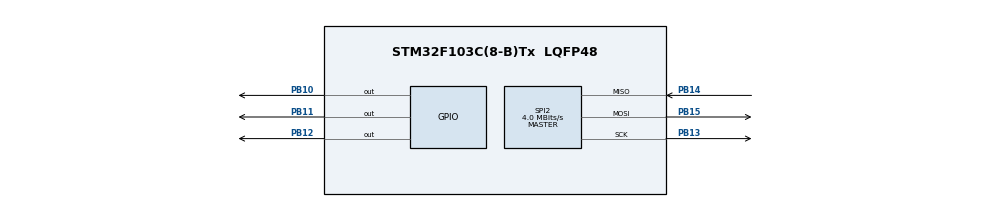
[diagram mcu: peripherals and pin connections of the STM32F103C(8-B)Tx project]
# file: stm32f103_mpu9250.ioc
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Mcu.Family=STM32F1
Mcu.Name=STM32F103C(8-B)Tx
Mcu.Package=LQFP48
NVIC.PriorityGroup=NVIC_PRIORITYGROUP_4
PA13.Mode=Serial_Wire
PA13.Signal=SYS_JTMS-SWDIO
PA14.Mode=Serial_Wire
PA14.Signal=SYS_JTCK-SWCLK
PB10.Signal=GPIO_Output
PB11.Signal=GPIO_Output
PB12.Signal=GPIO_Output
PB13.Mode=Full_Duplex_Master
PB13.Signal=SPI2_SCK
PB14.Mode=Full_Duplex_Master
PB14.Signal=SPI2_MISO
PB15.Mode=Full_Duplex_Master
PB15.Signal=SPI2_MOSI
PC14-OSC32_IN.Mode=LSE-External-Oscillator
PC14-OSC32_IN.Signal=RCC_OSC32_IN
PC15-OSC32_OUT.Mode=LSE-External-Oscillator
PC15-OSC32_OUT.Signal=RCC_OSC32_OUT
PD0-OSC_IN.Mode=HSE-External-Oscillator
PD0-OSC_IN.Signal=RCC_OSC_IN
PD1-OSC_OUT.Mode=HSE-External-Oscillator
PD1-OSC_OUT.Signal=RCC_OSC_OUT
ProjectManager.HeapSize=0x200
ProjectManager.StackSize=0x400
ProjectManager.TargetToolchain=STM32CubeIDE
RCC.APB1Freq_Value=8000000
RCC.APB2Freq_Value=8000000
SPI2.CalculateBaudRate=4.0 MBits/s
SPI2.Direction=SPI_DIRECTION_2LINES
SPI2.Mode=SPI_MODE_MASTER
SPI2.VirtualType=VM_MASTER
board=custom

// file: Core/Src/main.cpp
/* USER CODE BEGIN Header */
/**
  ******************************************************************************
  * @file           : main.c
  * @brief          : Main program body
  ******************************************************************************
  * @attention
  *
  * <h2><center>&copy; Copyright (c) 2020 STMicroelectronics.
  * All rights reserved.</center></h2>
  *
  * This software component is licensed by ST under BSD 3-Clause license,
  * the "License"; You may not use this file except in compliance with the
  * License. You may obtain a copy of the License at:
  *                        opensource.org/licenses/BSD-3-Clause
  *
  ******************************************************************************
  */
/* USER CODE END Header */

#include "../../Platform/PlatformInclude.h"

SPI_HandleTypeDef hspi2;

void SystemClock_Config(void);
static void MX_GPIO_Init(void);
static void MX_SPI2_Init(void);

int main(void)
{

  /* MCU Configuration--------------------------------------------------------*/

  /* Reset of all peripherals, Initializes the Flash interface and the Systick. */
  HAL_Init();

  /* Configure the system clock */
  SystemClock_Config();

  /* Initialize all configured peripherals */
  MX_GPIO_Init();
  MX_SPI2_Init();
  /* USER CODE BEGIN 2 */
  Mpu9250* Imu = Mpu9250::getInstance();
  Imu->configImu(MPU_SCALE_8G, MPU_SCALE_1000DPS);
  ImuData data = {0};
  /* USER CODE END 2 */

  /* Infinite loop */
  while (1)
  {
	Imu->getData(data);
	HAL_Delay(100);
  }
}

void SystemClock_Config(void)
{
  RCC_OscInitTypeDef RCC_OscInitStruct = {0};
  RCC_ClkInitTypeDef RCC_ClkInitStruct = {0};

  /** Initializes the CPU, AHB and APB busses clocks
  */
  RCC_OscInitStruct.OscillatorType = RCC_OSCILLATORTYPE_HSI;
  RCC_OscInitStruct.HSIState = RCC_HSI_ON;
  RCC_OscInitStruct.HSICalibrationValue = RCC_HSICALIBRATION_DEFAULT;
  RCC_OscInitStruct.PLL.PLLState = RCC_PLL_NONE;
  if (HAL_RCC_OscConfig(&RCC_OscInitStruct) != HAL_OK)
  {
    Error_Handler();
  }
  /** Initializes the CPU, AHB and APB busses clocks
  */
  RCC_ClkInitStruct.ClockType = RCC_CLOCKTYPE_HCLK|RCC_CLOCKTYPE_SYSCLK
                              |RCC_CLOCKTYPE_PCLK1|RCC_CLOCKTYPE_PCLK2;
  RCC_ClkInitStruct.SYSCLKSource = RCC_SYSCLKSOURCE_HSI;
  RCC_ClkInitStruct.AHBCLKDivider = RCC_SYSCLK_DIV1;
  RCC_ClkInitStruct.APB1CLKDivider = RCC_HCLK_DIV1;
  RCC_ClkInitStruct.APB2CLKDivider = RCC_HCLK_DIV1;

  if (HAL_RCC_ClockConfig(&RCC_ClkInitStruct, FLASH_LATENCY_0) != HAL_OK)
  {
    Error_Handler();
  }
}

static void MX_SPI2_Init(void)
{

  /* SPI2 parameter configuration*/
  hspi2.Instance = SPI2;
  hspi2.Init.Mode = SPI_MODE_MASTER;
  hspi2.Init.Direction = SPI_DIRECTION_2LINES;
  hspi2.Init.DataSize = SPI_DATASIZE_8BIT;
  hspi2.Init.CLKPolarity = SPI_POLARITY_LOW;
  hspi2.Init.CLKPhase = SPI_PHASE_1EDGE;
  hspi2.Init.NSS = SPI_NSS_SOFT;
  hspi2.Init.BaudRatePrescaler = SPI_BAUDRATEPRESCALER_2;
  hspi2.Init.FirstBit = SPI_FIRSTBIT_MSB;
  hspi2.Init.TIMode = SPI_TIMODE_DISABLE;
  hspi2.Init.CRCCalculation = SPI_CRCCALCULATION_DISABLE;
  hspi2.Init.CRCPolynomial = 10;
  if (HAL_SPI_Init(&hspi2) != HAL_OK)
  {
    Error_Handler();
  }

}

static void MX_GPIO_Init(void)
{
  GPIO_InitTypeDef GPIO_InitStruct = {0};

  /* GPIO Ports Clock Enable */
  __HAL_RCC_GPIOC_CLK_ENABLE();
  __HAL_RCC_GPIOD_CLK_ENABLE();
  __HAL_RCC_GPIOB_CLK_ENABLE();
  __HAL_RCC_GPIOA_CLK_ENABLE();

  /*Configure GPIO pin Output Level */
  HAL_GPIO_WritePin(GPIOB, GPIO_PIN_10|GPIO_PIN_11|GPIO_PIN_12, GPIO_PIN_RESET);

  /*Configure GPIO pins : PB10 PB11 PB12 */
  GPIO_InitStruct.Pin = GPIO_PIN_10|GPIO_PIN_11|GPIO_PIN_12;
  GPIO_InitStruct.Mode = GPIO_MODE_OUTPUT_PP;
  GPIO_InitStruct.Pull = GPIO_NOPULL;
  GPIO_InitStruct.Speed = GPIO_SPEED_FREQ_LOW;
  HAL_GPIO_Init(GPIOB, &GPIO_InitStruct);

}

void Error_Handler(void)
{
}

/************************ (C) COPYRIGHT STMicroelectronics *****END OF FILE****/
